# MINI register map
File version: 1.0
Registers are 32-bit, read-write, reset 0x0 unless marked. A register's access mark holds for its fields unless they carry their own. Offsets are from the block's base; lines under a group give offsets from that group; [hi:lo] are bit positions; {n}, {i} and the like mark numbered series; 'fields as' and 'values as' point back to an identical list; <NAME> marks a mode.

## Memory map
0x40000000 PA
0x40001000 PB
0x40002000 PC
{0x50000000+0x1000*n} UART{n} (n=0..1)

## PA
Base 0x40000000
Same registers: PB 0x40001000
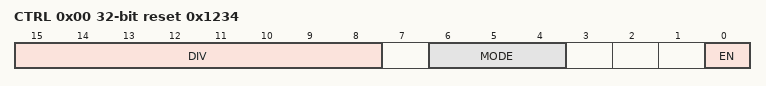
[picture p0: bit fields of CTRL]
0x00 CTRL reset 0x1234
  [15:8] DIV, [6:4] MODE ro, [0] EN
0x04 STAT 16-bit ro
{0x10+4i} DATA{i} (i=0..2)
{0x100+0x100*i} CH{i} (i=0..1) group
  0x08 CFG reset 0xFF

## PC
Base 0x40002000
0x00 CTRL reset 0xABCD
0x04 STAT 16-bit ro
{0x10+4i} DATA{i} (i=0..2)
{0x100+0x100*i} CH{i} (i=0..1) group
  0x08 CFG reset 0xFF

## UART{n}
Base 0x50000000; array of 2, step 0x1000
0x00 TX
